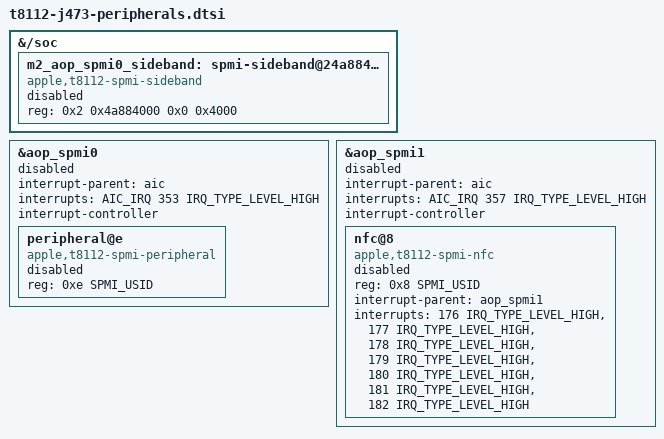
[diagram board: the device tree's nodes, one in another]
// SPDX-License-Identifier: GPL-2.0+ OR MIT
/* Additional T8112 hardware resources. Keep unqualified blocks disabled. */

&{/soc} {
	m2_aop_spmi0_sideband: spmi-sideband@24a884000 {
		compatible = "apple,t8112-spmi-sideband", "apple,spmi-sideband";
		reg = <0x2 0x4a884000 0x0 0x4000>;
		status = "disabled";
	};

};

&aop_spmi0 {
	interrupt-parent = <&aic>;
	interrupts = <AIC_IRQ 353 IRQ_TYPE_LEVEL_HIGH>;
	#address-cells = <2>;
	#size-cells = <0>;
	interrupt-controller;
	#interrupt-cells = <2>;
	status = "disabled";

	peripheral@e {
		compatible = "apple,t8112-spmi-peripheral",
			"apple,spmi-peripheral";
		reg = <0xe SPMI_USID>;
		status = "disabled";
	};
};

&aop_spmi1 {
	interrupt-parent = <&aic>;
	interrupts = <AIC_IRQ 357 IRQ_TYPE_LEVEL_HIGH>;
	#address-cells = <2>;
	#size-cells = <0>;
	interrupt-controller;
	#interrupt-cells = <2>;
	status = "disabled";

	nfc@8 {
		compatible = "apple,t8112-spmi-nfc",
			"apple,spmi-nfc";
		reg = <0x8 SPMI_USID>;
		interrupt-parent = <&aop_spmi1>;
		interrupts = <176 IRQ_TYPE_LEVEL_HIGH>,
			<177 IRQ_TYPE_LEVEL_HIGH>,
			<178 IRQ_TYPE_LEVEL_HIGH>,
			<179 IRQ_TYPE_LEVEL_HIGH>,
			<180 IRQ_TYPE_LEVEL_HIGH>,
			<181 IRQ_TYPE_LEVEL_HIGH>,
			<182 IRQ_TYPE_LEVEL_HIGH>;
		status = "disabled";
	};
};
